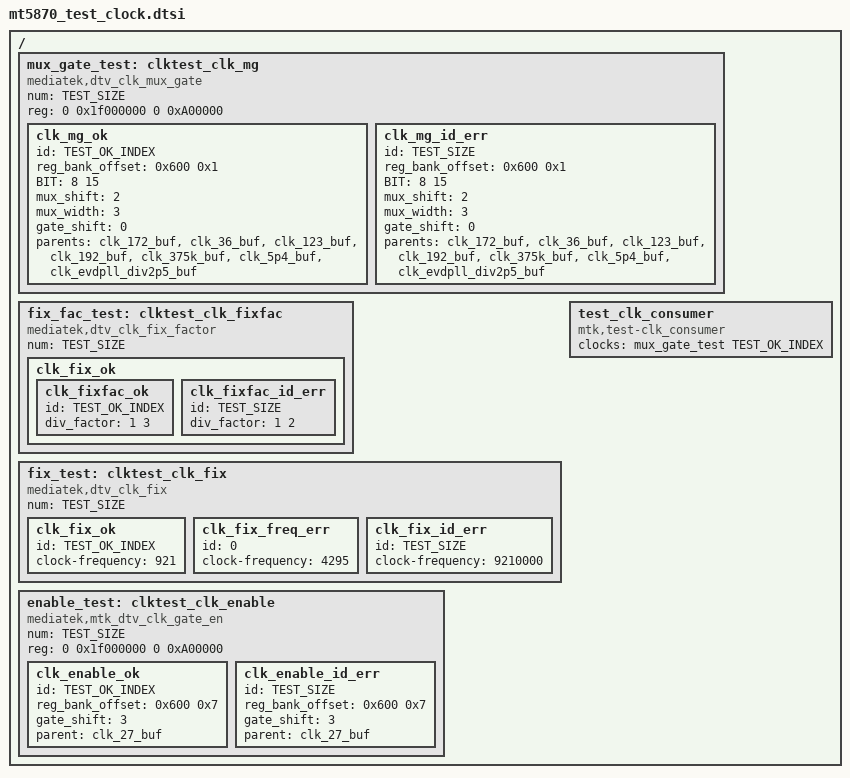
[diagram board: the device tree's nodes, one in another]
#define TEST_SIZE 3
#define TEST_OK_INDEX (TEST_SIZE-1)
/ {

	mux_gate_test: clktest_clk_mg {
		#clock-cells = <1>;
		compatible = "mediatek,dtv_clk_mux_gate";
		num = <TEST_SIZE>;
		reg = <0 0x1f000000 0 0xA00000>; /* this is riu start address */

		clk_mg_ok {
			id = <TEST_OK_INDEX>;
			reg_bank_offset = <0x600 0x1>; /* bank: 0x6, 16-bit addr : 0x1 */
			BIT = <8 15>; /* control bit 8 to 15 */
			mux_shift = <2>; /* --> start bit of mux control */
			mux_width = <3>; /* --> bit number of mux control */
			gate_shift = <0>; /* --> start_bit of gate conctrol */
			parents = "clk_172_buf", "clk_36_buf", "clk_123_buf", "clk_192_buf", "clk_375k_buf", "clk_5p4_buf", "clk_evdpll_div2p5_buf";
		};
		clk_mg_id_err {
			id = <TEST_SIZE>;
			reg_bank_offset = <0x600 0x1>; /* bank: 0x6, 16-bit addr : 0x1 */
			BIT = <8 15>; /* control bit 8 to 15 */
			mux_shift = <2>; /* --> start bit of mux control */
			mux_width = <3>; /* --> bit number of mux control */
			gate_shift = <0>; /* --> start_bit of gate conctrol */
			parents = "clk_172_buf", "clk_36_buf", "clk_123_buf", "clk_192_buf", "clk_375k_buf", "clk_5p4_buf", "clk_evdpll_div2p5_buf";
		};

	};

	fix_fac_test: clktest_clk_fixfac {
		#clock-cells = <1>;
		compatible = "mediatek,dtv_clk_fix_factor";
		num = <TEST_SIZE>;
		clk_fix_ok {
			clk_fixfac_ok {
				id = <TEST_OK_INDEX>;
				div_factor = <1 3>;
			};
			clk_fixfac_id_err {
				id = <TEST_SIZE>;
				div_factor = <1 2>;
			};
		};
	};

	fix_test: clktest_clk_fix {
		#clock-cells = <1>;
		compatible = "mediatek,dtv_clk_fix";
		num = <TEST_SIZE>;
		clk_fix_ok {
			id = <TEST_OK_INDEX>;
			clock-frequency = <921>;
		};
		clk_fix_freq_err {
			id = <0>;
			clock-frequency = <4295>; /* (2^32-1)/MHZ */
		};
		clk_fix_id_err {
			id = <TEST_SIZE>;
			clock-frequency = <9210000>;
		};

	};

	enable_test: clktest_clk_enable {
		#clock-cells = <1>;
		compatible = "mediatek,mtk_dtv_clk_gate_en";
		num = <TEST_SIZE>;
		reg = <0 0x1f000000 0 0xA00000>; /* this is riu start address */

		clk_enable_ok {
			id = <TEST_OK_INDEX>;
			reg_bank_offset = <0x600 0x7>; /* bank: 0x6, 16-bit addr : 0x9 */
			gate_shift = <3>;
			parent = "clk_27_buf";
		};
		clk_enable_id_err {
			id = <TEST_SIZE>;
			reg_bank_offset = <0x600 0x7>; /* bank: 0x6, 16-bit addr : 0x9 */
			gate_shift = <3>;
			parent = "clk_27_buf";
		};
	};

	test_clk_consumer {
		compatible = "mtk,test-clk_consumer";
		clocks = <&mux_gate_test TEST_OK_INDEX>;
		clock-names = "ooxx";
	};

};
